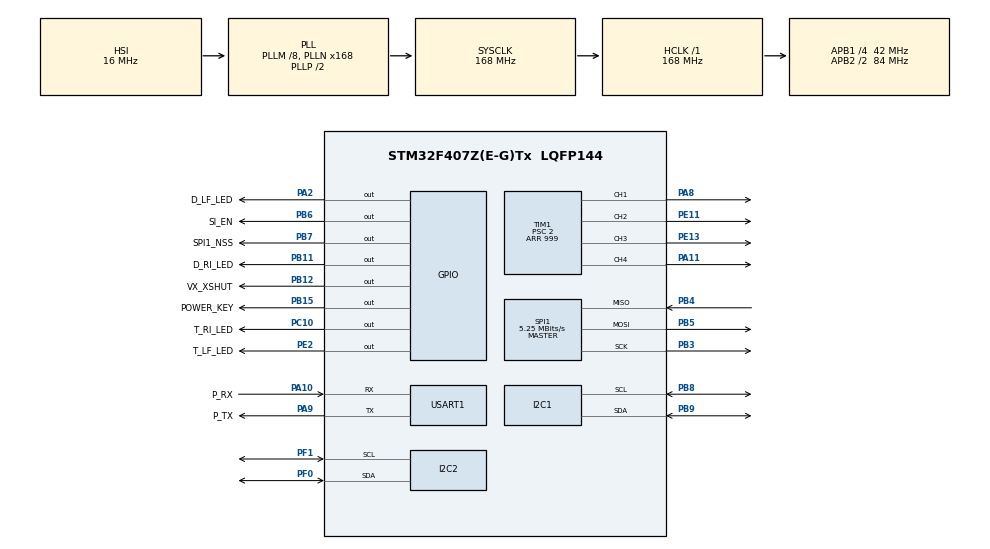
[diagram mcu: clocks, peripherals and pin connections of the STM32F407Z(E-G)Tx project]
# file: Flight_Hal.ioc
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I2C1.I2C_Mode=I2C_Fast
Mcu.Family=STM32F4
Mcu.Name=STM32F407Z(E-G)Tx
Mcu.Package=LQFP144
NVIC.PriorityGroup=NVIC_PRIORITYGROUP_4
PA10.GPIO_Label=P_RX
PA10.Mode=Asynchronous
PA10.Signal=USART1_RX
PA11.GPIO_Speed=GPIO_SPEED_FREQ_HIGH
PA11.Signal=S_TIM1_CH4
PA13.Mode=Serial_Wire
PA13.Signal=SYS_JTMS-SWDIO
PA14.Mode=Serial_Wire
PA14.Signal=SYS_JTCK-SWCLK
PA2.GPIO_Label=D_LF_LED
PA2.GPIO_ModeDefaultOutputPP=GPIO_MODE_OUTPUT_OD
PA2.GPIO_PuPd=GPIO_NOPULL
PA2.PinState=GPIO_PIN_SET
PA2.Signal=GPIO_Output
PA8.GPIO_Speed=GPIO_SPEED_FREQ_HIGH
PA8.Signal=S_TIM1_CH1
PA9.GPIO_Label=P_TX
PA9.Mode=Asynchronous
PA9.Signal=USART1_TX
PB11.GPIO_Label=D_RI_LED
PB11.GPIO_ModeDefaultOutputPP=GPIO_MODE_OUTPUT_OD
PB11.GPIO_PuPd=GPIO_NOPULL
PB11.PinState=GPIO_PIN_SET
PB11.Signal=GPIO_Output
PB12.GPIO_Label=VX_XSHUT
PB12.PinState=GPIO_PIN_SET
PB12.Signal=GPIO_Output
PB15.GPIO_Label=POWER_KEY
PB15.GPIO_ModeDefaultOutputPP=GPIO_MODE_OUTPUT_OD
PB15.GPIO_PuPd=GPIO_PULLUP
PB15.GPIO_Speed=GPIO_SPEED_FREQ_LOW
PB15.PinState=GPIO_PIN_SET
PB15.Signal=GPIO_Output
PB3.Mode=Full_Duplex_Master
PB3.Signal=SPI1_SCK
PB4.Mode=Full_Duplex_Master
PB4.Signal=SPI1_MISO
PB5.Mode=Full_Duplex_Master
PB5.Signal=SPI1_MOSI
PB6.GPIO_Label=SI_EN
PB6.PinState=GPIO_PIN_RESET
PB6.Signal=GPIO_Output
PB7.GPIO_Label=SPI1_NSS
PB7.PinState=GPIO_PIN_SET
PB7.Signal=GPIO_Output
PB8.Mode=I2C
PB8.Signal=I2C1_SCL
PB9.Mode=I2C
PB9.Signal=I2C1_SDA
PC10.GPIO_Label=T_RI_LED
PC10.GPIO_ModeDefaultOutputPP=GPIO_MODE_OUTPUT_OD
PC10.GPIO_PuPd=GPIO_NOPULL
PC10.PinState=GPIO_PIN_SET
PC10.Signal=GPIO_Output
PC14-OSC32_IN.Mode=LSE-External-Oscillator
PC14-OSC32_IN.Signal=RCC_OSC32_IN
PC15-OSC32_OUT.Mode=LSE-External-Oscillator
PC15-OSC32_OUT.Signal=RCC_OSC32_OUT
PE11.GPIO_Speed=GPIO_SPEED_FREQ_HIGH
PE11.Signal=S_TIM1_CH2
PE13.GPIO_Speed=GPIO_SPEED_FREQ_HIGH
PE13.Signal=S_TIM1_CH3
PE2.GPIO_Label=T_LF_LED
PE2.GPIO_ModeDefaultOutputPP=GPIO_MODE_OUTPUT_OD
PE2.GPIO_PuPd=GPIO_NOPULL
PE2.PinState=GPIO_PIN_SET
PE2.Signal=GPIO_Output
PF0.Mode=I2C
PF0.Signal=I2C2_SDA
PF1.Mode=I2C
PF1.Signal=I2C2_SCL
PH0-OSC_IN.Mode=HSE-External-Oscillator
PH0-OSC_IN.Signal=RCC_OSC_IN
PH1-OSC_OUT.Mode=HSE-External-Oscillator
PH1-OSC_OUT.Signal=RCC_OSC_OUT
ProjectManager.HeapSize=0x200
ProjectManager.StackSize=0x400
ProjectManager.TargetToolchain=CMake
RCC.48MHZClocksFreq_Value=84000000
RCC.AHBFreq_Value=168000000
RCC.APB1CLKDivider=RCC_HCLK_DIV4
RCC.APB1Freq_Value=42000000
RCC.APB1TimFreq_Value=84000000
RCC.APB2CLKDivider=RCC_HCLK_DIV2
RCC.APB2Freq_Value=84000000
RCC.APB2TimFreq_Value=168000000
RCC.CortexFreq_Value=168000000
RCC.HCLKFreq_Value=168000000
RCC.HSE_VALUE=8000000
RCC.HSI_VALUE=16000000
RCC.PLLM=8
RCC.PLLN=168
RCC.SYSCLKFreq_VALUE=168000000
RCC.SYSCLKSource=RCC_SYSCLKSOURCE_PLLCLK
RCC.VCOOutputFreq_Value=336000000
SH.S_TIM1_CH1.0=TIM1_CH1,PWM Generation1 CH1
SH.S_TIM1_CH2.0=TIM1_CH2,PWM Generation2 CH2
SH.S_TIM1_CH3.0=TIM1_CH3,PWM Generation3 CH3
SH.S_TIM1_CH4.0=TIM1_CH4,PWM Generation4 CH4
SPI1.BaudRatePrescaler=SPI_BAUDRATEPRESCALER_16
SPI1.CalculateBaudRate=5.25 MBits/s
SPI1.Direction=SPI_DIRECTION_2LINES
SPI1.Mode=SPI_MODE_MASTER
SPI1.VirtualType=VM_MASTER
TIM1.Channel-PWM\ Generation1\ CH1=TIM_CHANNEL_1
TIM1.Channel-PWM\ Generation2\ CH2=TIM_CHANNEL_2
TIM1.Channel-PWM\ Generation3\ CH3=TIM_CHANNEL_3
TIM1.Channel-PWM\ Generation4\ CH4=TIM_CHANNEL_4
TIM1.Period=999
TIM1.Prescaler=2
USART1.VirtualMode=VM_ASYNC
VP_TIM1_VS_ClockSourceINT.Mode=Internal
board=custom

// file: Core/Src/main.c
/* USER CODE BEGIN Header */
/**
  ******************************************************************************
  * @file           : main.c
  * @brief          : Main program body
  ******************************************************************************
  * @attention
  *
  * Copyright (c) 2026 STMicroelectronics.
  * All rights reserved.
  *
  * This software is licensed under terms that can be found in the LICENSE file
  * in the root directory of this software component.
  * If no LICENSE file comes with this software, it is provided AS-IS.
  *
  ******************************************************************************
  */
/* USER CODE END Header */
#include "main.h"
#include "i2c.h"
#include "spi.h"
#include "tim.h"
#include "usart.h"
#include "gpio.h"

/* USER CODE BEGIN Includes */
#include "Com_debug.h"
#include "APP_FreeRTOS_Task.h"
/* USER CODE END Includes */

void SystemClock_Config(void);

int main(void)
{

  /* MCU Configuration--------------------------------------------------------*/

  /* Reset of all peripherals, Initializes the Flash interface and the Systick. */
  HAL_Init();

  /* Configure the system clock */
  SystemClock_Config();

  /* Initialize all configured peripherals */
  MX_GPIO_Init();
  MX_USART1_UART_Init();
  MX_TIM1_Init();
  MX_SPI1_Init();
  MX_I2C1_Init();
  MX_I2C2_Init();
  /* USER CODE BEGIN 2 */
  //实现串口日志输出打印
  debug_printf("Hello, STM32F407!\r\n");
  Int_SI24R1_Init();
  //Int_MPU6050_Init();放到飞控任务中初始化，这样可以在飞控任务中进行零偏校准，得到更准确的测量值
  //启动FreeRTOS调度器
  APP_FreeRTOS_Task_Start();

  /* USER CODE END 2 */

  /* Infinite loop */
  while (1)
  {

  }
}

void SystemClock_Config(void)
{
  RCC_OscInitTypeDef RCC_OscInitStruct = {0};
  RCC_ClkInitTypeDef RCC_ClkInitStruct = {0};

  /** Configure the main internal regulator output voltage
  */
  __HAL_RCC_PWR_CLK_ENABLE();
  __HAL_PWR_VOLTAGESCALING_CONFIG(PWR_REGULATOR_VOLTAGE_SCALE1);

  /** Initializes the RCC Oscillators according to the specified parameters
  * in the RCC_OscInitTypeDef structure.
  */
  RCC_OscInitStruct.OscillatorType = RCC_OSCILLATORTYPE_HSI;
  RCC_OscInitStruct.HSIState = RCC_HSI_ON;
  RCC_OscInitStruct.HSICalibrationValue = RCC_HSICALIBRATION_DEFAULT;
  RCC_OscInitStruct.PLL.PLLState = RCC_PLL_ON;
  RCC_OscInitStruct.PLL.PLLSource = RCC_PLLSOURCE_HSI;
  RCC_OscInitStruct.PLL.PLLM = 8;
  RCC_OscInitStruct.PLL.PLLN = 168;
  RCC_OscInitStruct.PLL.PLLP = RCC_PLLP_DIV2;
  RCC_OscInitStruct.PLL.PLLQ = 4;
  if (HAL_RCC_OscConfig(&RCC_OscInitStruct) != HAL_OK)
  {
    Error_Handler();
  }

  /** Initializes the CPU, AHB and APB buses clocks
  */
  RCC_ClkInitStruct.ClockType = RCC_CLOCKTYPE_HCLK|RCC_CLOCKTYPE_SYSCLK
                              |RCC_CLOCKTYPE_PCLK1|RCC_CLOCKTYPE_PCLK2;
  RCC_ClkInitStruct.SYSCLKSource = RCC_SYSCLKSOURCE_PLLCLK;
  RCC_ClkInitStruct.AHBCLKDivider = RCC_SYSCLK_DIV1;
  RCC_ClkInitStruct.APB1CLKDivider = RCC_HCLK_DIV4;
  RCC_ClkInitStruct.APB2CLKDivider = RCC_HCLK_DIV2;

  if (HAL_RCC_ClockConfig(&RCC_ClkInitStruct, FLASH_LATENCY_5) != HAL_OK)
  {
    Error_Handler();
  }
}

void Error_Handler(void)
{
  __disable_irq();
  while (1)
  {
  }
}
